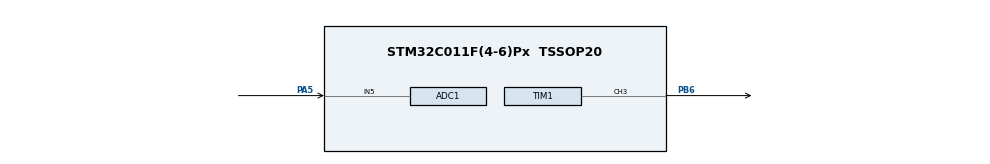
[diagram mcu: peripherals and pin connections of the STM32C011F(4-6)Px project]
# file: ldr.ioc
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ADC1.Channel-0\#ChannelRegularConversion=ADC_CHANNEL_5
ADC1.NbrOfConversionFlag=1
ADC1.Rank-0\#ChannelRegularConversion=1
ADC1.SamplingTime-0\#ChannelRegularConversion=ADC_SAMPLINGTIME_COMMON_1
ADC1.SelectedChannel=ADC_CHANNEL_5
ADC1.master=1
Mcu.Family=STM32C0
Mcu.Name=STM32C011F(4-6)Px
Mcu.Package=TSSOP20
PA13.Mode=Serial_Wire
PA13.Signal=DEBUG_SWDIO
PA14-BOOT0.Mode=Serial_Wire
PA14-BOOT0.Signal=DEBUG_SWCLK
PA5.Mode=IN5
PA5.Signal=ADC1_IN5
PB6.Signal=S_TIM1_CH3
ProjectManager.HeapSize=0x200
ProjectManager.StackSize=0x400
ProjectManager.TargetToolchain=STM32CubeIDE
RCC.ADCFreq_Value=48000000
RCC.AHBFreq_Value=48000000
RCC.CortexFreq_Value=48000000
RCC.EXTERNAL_CLOCK_VALUE=12288000
RCC.HCLKFreq_Value=48000000
RCC.HSE_VALUE=8000000
RCC.HSISYSCLKDivider=RCC_HSI_DIV1
RCC.HSI_VALUE=48000000
RCC.LSE_VALUE=32768
RCC.SYSCLKFreq_VALUE=48000000
SH.S_TIM1_CH3.0=TIM1_CH3,PWM Generation3 CH3
TIM1.Channel-PWM\ Generation3\ CH3=TIM_CHANNEL_3
TIM1.Period=1000-1
TIM1.Prescaler=48-1
VP_TIM1_VS_ClockSourceINT.Mode=Internal
board=custom

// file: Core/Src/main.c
/* USER CODE BEGIN Header */
/**
  ******************************************************************************
  * @file           : main.c
  * @brief          : Main program body
  ******************************************************************************
  * @attention
  *
  * Copyright (c) 2024 STMicroelectronics.
  * All rights reserved.
  *
  * This software is licensed under terms that can be found in the LICENSE file
  * in the root directory of this software component.
  * If no LICENSE file comes with this software, it is provided AS-IS.
  *
  ******************************************************************************
  */
/* USER CODE END Header */
#include "main.h"

ADC_HandleTypeDef hadc1;

TIM_HandleTypeDef htim1;

/* USER CODE BEGIN PV */
uint32_t leitura;
uint32_t pwm;

/* USER CODE END PV */

void SystemClock_Config(void);
static void MX_GPIO_Init(void);
static void MX_ADC1_Init(void);
static void MX_TIM1_Init(void);

/* Main program body */
int main(void)
{
  HAL_Init();
  SystemClock_Config();
  MX_GPIO_Init();
  MX_ADC1_Init();
  MX_TIM1_Init();

  // Inicia o PWM no canal especificado
  HAL_TIM_PWM_Start(&htim1, TIM_CHANNEL_3);

  while (1)
  {
	// leitura ADC pelo meotod polling
    HAL_ADC_Start(&hadc1);
    if (HAL_ADC_PollForConversion(&hadc1, 1000) == HAL_OK) {
      leitura = HAL_ADC_GetValue(&hadc1);
    }
    HAL_ADC_Stop(&hadc1);
    // Inverte a lógica: quanto maior a leitura do ADC (mais luz), maior o PWM
    pwm = 1000 - ((leitura * 1000) / 4095);
    // Atualiza a intensidade do LED
    __HAL_TIM_SET_COMPARE(&htim1, TIM_CHANNEL_3, pwm);
  }
}

void SystemClock_Config(void)
{
  RCC_OscInitTypeDef RCC_OscInitStruct = {0};
  RCC_ClkInitTypeDef RCC_ClkInitStruct = {0};

  /** Initializes the RCC Oscillators according to the specified parameters
  * in the RCC_OscInitTypeDef structure.
  */
  RCC_OscInitStruct.OscillatorType = RCC_OSCILLATORTYPE_HSI;
  RCC_OscInitStruct.HSIState = RCC_HSI_ON;
  RCC_OscInitStruct.HSIDiv = RCC_HSI_DIV1;
  RCC_OscInitStruct.HSICalibrationValue = RCC_HSICALIBRATION_DEFAULT;
  if (HAL_RCC_OscConfig(&RCC_OscInitStruct) != HAL_OK)
  {
    Error_Handler();
  }

  /** Initializes the CPU, AHB and APB buses clocks
  */
  RCC_ClkInitStruct.ClockType = RCC_CLOCKTYPE_HCLK|RCC_CLOCKTYPE_SYSCLK
                              |RCC_CLOCKTYPE_PCLK1;
  RCC_ClkInitStruct.SYSCLKSource = RCC_SYSCLKSOURCE_HSI;
  RCC_ClkInitStruct.SYSCLKDivider = RCC_SYSCLK_DIV1;
  RCC_ClkInitStruct.AHBCLKDivider = RCC_HCLK_DIV1;
  RCC_ClkInitStruct.APB1CLKDivider = RCC_APB1_DIV1;

  if (HAL_RCC_ClockConfig(&RCC_ClkInitStruct, FLASH_LATENCY_1) != HAL_OK)
  {
    Error_Handler();
  }
}

static void MX_ADC1_Init(void)
{

  ADC_ChannelConfTypeDef sConfig = {0};

  /** Configure the global features of the ADC (Clock, Resolution, Data Alignment and number of conversion)
  */
  hadc1.Instance = ADC1;
  hadc1.Init.ClockPrescaler = ADC_CLOCK_SYNC_PCLK_DIV2;
  hadc1.Init.Resolution = ADC_RESOLUTION_12B;
  hadc1.Init.DataAlign = ADC_DATAALIGN_RIGHT;
  hadc1.Init.ScanConvMode = ADC_SCAN_DISABLE;
  hadc1.Init.EOCSelection = ADC_EOC_SINGLE_CONV;
  hadc1.Init.LowPowerAutoWait = DISABLE;
  hadc1.Init.LowPowerAutoPowerOff = DISABLE;
  hadc1.Init.ContinuousConvMode = DISABLE;
  hadc1.Init.NbrOfConversion = 1;
  hadc1.Init.DiscontinuousConvMode = DISABLE;
  hadc1.Init.ExternalTrigConv = ADC_SOFTWARE_START;
  hadc1.Init.ExternalTrigConvEdge = ADC_EXTERNALTRIGCONVEDGE_NONE;
  hadc1.Init.DMAContinuousRequests = DISABLE;
  hadc1.Init.Overrun = ADC_OVR_DATA_PRESERVED;
  hadc1.Init.SamplingTimeCommon1 = ADC_SAMPLETIME_1CYCLE_5;
  hadc1.Init.SamplingTimeCommon2 = ADC_SAMPLETIME_1CYCLE_5;
  hadc1.Init.OversamplingMode = DISABLE;
  hadc1.Init.TriggerFrequencyMode = ADC_TRIGGER_FREQ_HIGH;
  if (HAL_ADC_Init(&hadc1) != HAL_OK)
  {
    Error_Handler();
  }

  /** Configure Regular Channel
  */
  sConfig.Channel = ADC_CHANNEL_5;
  sConfig.Rank = ADC_REGULAR_RANK_1;
  sConfig.SamplingTime = ADC_SAMPLINGTIME_COMMON_1;
  if (HAL_ADC_ConfigChannel(&hadc1, &sConfig) != HAL_OK)
  {
    Error_Handler();
  }

}

static void MX_TIM1_Init(void)
{

  TIM_ClockConfigTypeDef sClockSourceConfig = {0};
  TIM_MasterConfigTypeDef sMasterConfig = {0};
  TIM_OC_InitTypeDef sConfigOC = {0};
  TIM_BreakDeadTimeConfigTypeDef sBreakDeadTimeConfig = {0};

  htim1.Instance = TIM1;
  htim1.Init.Prescaler = 48-1;
  htim1.Init.CounterMode = TIM_COUNTERMODE_UP;
  htim1.Init.Period = 1000-1;
  htim1.Init.ClockDivision = TIM_CLOCKDIVISION_DIV1;
  htim1.Init.RepetitionCounter = 0;
  htim1.Init.AutoReloadPreload = TIM_AUTORELOAD_PRELOAD_DISABLE;
  if (HAL_TIM_Base_Init(&htim1) != HAL_OK)
  {
    Error_Handler();
  }
  sClockSourceConfig.ClockSource = TIM_CLOCKSOURCE_INTERNAL;
  if (HAL_TIM_ConfigClockSource(&htim1, &sClockSourceConfig) != HAL_OK)
  {
    Error_Handler();
  }
  if (HAL_TIM_PWM_Init(&htim1) != HAL_OK)
  {
    Error_Handler();
  }
  sMasterConfig.MasterOutputTrigger = TIM_TRGO_RESET;
  sMasterConfig.MasterOutputTrigger2 = TIM_TRGO2_RESET;
  sMasterConfig.MasterSlaveMode = TIM_MASTERSLAVEMODE_DISABLE;
  if (HAL_TIMEx_MasterConfigSynchronization(&htim1, &sMasterConfig) != HAL_OK)
  {
    Error_Handler();
  }
  sConfigOC.OCMode = TIM_OCMODE_PWM1;
  sConfigOC.Pulse = 0;
  sConfigOC.OCPolarity = TIM_OCPOLARITY_HIGH;
  sConfigOC.OCNPolarity = TIM_OCNPOLARITY_HIGH;
  sConfigOC.OCFastMode = TIM_OCFAST_DISABLE;
  sConfigOC.OCIdleState = TIM_OCIDLESTATE_RESET;
  sConfigOC.OCNIdleState = TIM_OCNIDLESTATE_RESET;
  if (HAL_TIM_PWM_ConfigChannel(&htim1, &sConfigOC, TIM_CHANNEL_3) != HAL_OK)
  {
    Error_Handler();
  }
  sBreakDeadTimeConfig.OffStateRunMode = TIM_OSSR_DISABLE;
  sBreakDeadTimeConfig.OffStateIDLEMode = TIM_OSSI_DISABLE;
  sBreakDeadTimeConfig.LockLevel = TIM_LOCKLEVEL_OFF;
  sBreakDeadTimeConfig.DeadTime = 0;
  sBreakDeadTimeConfig.BreakState = TIM_BREAK_DISABLE;
  sBreakDeadTimeConfig.BreakPolarity = TIM_BREAKPOLARITY_HIGH;
  sBreakDeadTimeConfig.BreakFilter = 0;
  sBreakDeadTimeConfig.BreakAFMode = TIM_BREAK_AFMODE_INPUT;
  sBreakDeadTimeConfig.Break2State = TIM_BREAK2_DISABLE;
  sBreakDeadTimeConfig.Break2Polarity = TIM_BREAK2POLARITY_HIGH;
  sBreakDeadTimeConfig.Break2Filter = 0;
  sBreakDeadTimeConfig.Break2AFMode = TIM_BREAK_AFMODE_INPUT;
  sBreakDeadTimeConfig.AutomaticOutput = TIM_AUTOMATICOUTPUT_DISABLE;
  if (HAL_TIMEx_ConfigBreakDeadTime(&htim1, &sBreakDeadTimeConfig) != HAL_OK)
  {
    Error_Handler();
  }
  HAL_TIM_MspPostInit(&htim1);

}

static void MX_GPIO_Init(void)
{

  /* GPIO Ports Clock Enable */
  __HAL_RCC_GPIOA_CLK_ENABLE();
  __HAL_RCC_GPIOB_CLK_ENABLE();

}

void Error_Handler(void)
{
  __disable_irq();
  while (1)
  {
  }
}
